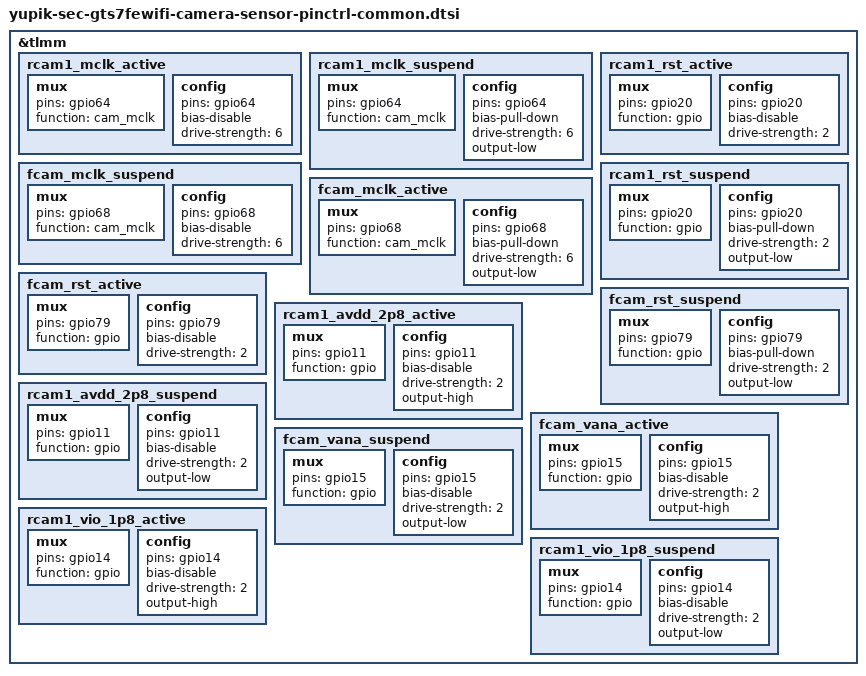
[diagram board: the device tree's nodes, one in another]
/* Copyright (c) 2020, The Linux Foundation. All rights reserved.
 *
 * This program is free software; you can redistribute it and/or modify
 * it under the terms of the GNU General Public License version 2 and
 * only version 2 as published by the Free Software Foundation.
 *
 * This program is distributed in the hope that it will be useful,
 * but WITHOUT ANY WARRANTY; without even the implied warranty of
 * MERCHANTABILITY or FITNESS FOR A PARTICULAR PURPOSE.  See the
 * GNU General Public License for more details.
 */


&tlmm {
	rcam1_mclk_active: rcam1_mclk_active {
		/* Main Rear MCLK */
		mux {
			pins = "gpio64";
			function = "cam_mclk";
		};
		config {
			pins = "gpio64";
			bias-disable; /* No PULL */
			drive-strength = <6>; /* 6 MA */
		};
	};

	rcam1_mclk_suspend: rcam1_mclk_suspend {
	/* Main Rear MCLK */
		mux {
			pins = "gpio64";
			function = "cam_mclk";
		};
		config {
			pins = "gpio64";
			bias-pull-down; /* No PULL */
			drive-strength = <6>; /* 6 MA */
			output-low;
		};
	};
	fcam_mclk_suspend: fcam_mclk_suspend {
		/* Front MCLK */
		mux {
			pins = "gpio68";
			function = "cam_mclk";
		};
		config {
			pins = "gpio68";
			bias-disable; /* No PULL */
			drive-strength = <6>; /* 6 MA */
		};
	};

	fcam_mclk_active: fcam_mclk_active {
	/* Front MCLK */
		mux {
			pins = "gpio68";
			function = "cam_mclk";
		};
		config {
			pins = "gpio68";
			bias-pull-down; /* No PULL */
			drive-strength = <6>; /* 6 MA */
			output-low;

		};
	};
	rcam1_rst_active: rcam1_rst_active {
	/* Main Rear reset */
		mux {
			pins = "gpio20";
			function = "gpio";
		};
		config {
			pins = "gpio20";
			bias-disable; /* No PULL */
			drive-strength = <2>; /* 2 MA */
		};
	};
	rcam1_rst_suspend: rcam1_rst_suspend {
	/* Main Rear reset */
		mux {
			pins = "gpio20";
			function = "gpio";
		};
		config {
			pins = "gpio20";
			bias-pull-down; /* PULL DOWN */
			drive-strength = <2>; /* 2 MA */			output-low;
		};
	};	fcam_rst_active: fcam_rst_active {
	/* Front Cam RESET */
		mux {
			pins = "gpio79";
			function = "gpio";
		};
		config {
			pins = "gpio79";
			bias-disable; /* No PULL */
			drive-strength = <2>; /* 2 MA */
		};
	};

	fcam_rst_suspend: fcam_rst_suspend {
	/* Front Cam RESET */
		mux {
			pins = "gpio79";
			function = "gpio";
		};
		config {
			pins = "gpio79";
			bias-pull-down; /* PULL DOWN */
			drive-strength = <2>; /* 2 MA */			output-low;
		};
	};
	rcam1_avdd_2p8_active: rcam1_avdd_2p8_active {
	/* Rear VANA */
		mux {
			pins = "gpio11";
			function = "gpio";
		};
		config {
			pins = "gpio11";
			bias-disable; /* No PULL */
			drive-strength = <2>; /* 2 MA */			output-high;
		};
	};
	rcam1_avdd_2p8_suspend: rcam1_avdd_2p8_suspend {
	/* Rear VANA */
		mux {
			pins = "gpio11";
			function = "gpio";
		};
		config {
			pins = "gpio11";
			bias-disable; /* No PULL */
			drive-strength = <2>; /* 2 MA */			output-low;
		};
	};

	fcam_vana_active: fcam_vana_active {
	/* Front VANA */
		mux {
			pins = "gpio15";
			function = "gpio";
		};
		config {
			pins = "gpio15";
			bias-disable; /* No PULL */
			drive-strength = <2>; /* 2 MA */			output-high;
		};
	};

	fcam_vana_suspend: fcam_vana_suspend {
	/* Front VANA */
		mux {
			pins = "gpio15";
			function = "gpio";
		};
		config {
			pins = "gpio15";
			bias-disable; /* No PULL */
			drive-strength = <2>; /* 2 MA */			output-low;
		};
	};

	rcam1_vio_1p8_active: rcam1_vio_1p8_active {
	/* Rear,Front VIO */
		mux {
			pins = "gpio14";
			function = "gpio";
		};
		config {
			pins = "gpio14";
			bias-disable; /* No PULL */
			drive-strength = <2>; /* 2 MA */			output-high;
		};
	};
	rcam1_vio_1p8_suspend: rcam1_vio_1p8_suspend {
	/* Rear,Front VIO */
		mux {
			pins = "gpio14";
			function = "gpio";
		};
		config {
			pins = "gpio14";
			bias-disable; /* No PULL */
			drive-strength = <2>; /* 2 MA */			output-low;
		};
	};

};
